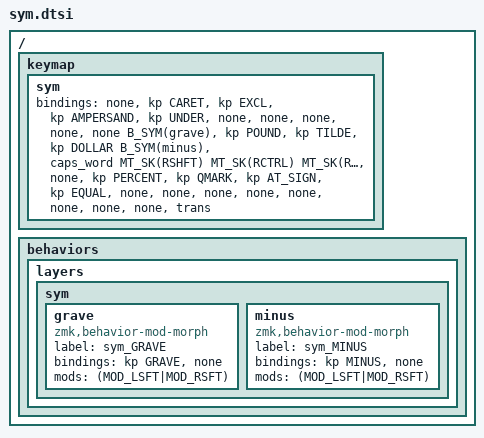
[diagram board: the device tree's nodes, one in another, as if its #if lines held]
// Copyright (c) 2022 The ZMK Contributors
// SPDX-License-Identifier: MIT

#define B_SYM(key) B_LAYER(sym, key)

/ {
    keymap {
        sym {
            bindings = <
        // ╭──────────────┬──────────────┬──────────────┬──────────────┬──────────────╮   ╭──────────────┬──────────────┬──────────────┬──────────────┬──────────────╮
        // │              |  ^           |  !           |  &           |  _           │   │              │              │              │              │              │
             &none          &kp CARET      &kp EXCL       &kp AMPERSAND  &kp UNDER          &none          &none          &none          &none          &none
        // ├──────────────┼──────────────┼──────────────┼──────────────┼──────────────┤   ├──────────────┼──────────────┼──────────────┼──────────────┼──────────────┤
        // │  `           |  #           |  ~           |  $           |  -           │   │              │  SHIFT       │  CONTROL     |  ALT         |  GUI         │
             B_SYM(grave)   &kp POUND      &kp TILDE      &kp DOLLAR     B_SYM(minus)       &caps_word     MT_SK(RSHFT)   MT_SK(RCTRL)   MT_SK(RALT)    MT_SK(RGUI)
        // ├──────────────┼──────────────┼──────────────┼──────────────┼──────────────┤   ├──────────────┼──────────────┼──────────────┼──────────────┼──────────────┤
        // │              |  %           |  ?           |  @           |  =           │   │              │              │              │              │              │
             &none          &kp PERCENT    &kp QMARK      &kp AT_SIGN    &kp EQUAL          &none          &none          &none          &none          &none
        // ╰──────────────┴──────────────┴──────────────┼──────────────┼──────────────┤   ├──────────────┼──────────────┼──────────────┴──────────────┴──────────────╯
#ifdef KEY_34
        //                                              ╭──────────────┬──────────────╮   ╭──────────────┬──────────────╮
        //                                              |              |              |   |              |              |
                                                          &none          &none              &none          &trans
        //                                              ╰──────────────┴──────────────╯   ╰──────────────┴──────────────╯
#else
        //                               ╭──────────────┬──────────────┬──────────────╮   ╭──────────────┬──────────────┬──────────────╮
        //                               |              |              |              |   |              |              |              |
                                           &none          &none          &none              &none          &trans         &none
        //                               ╰──────────────┴──────────────┴──────────────╯   ╰──────────────┴──────────────┴──────────────╯
#endif
            >;
        };
    };

    behaviors {
        layers {
            sym {
                grave {
                    compatible = "zmk,behavior-mod-morph";
                    label = "sym_GRAVE";
                    #binding-cells = <0>;
                    bindings = <&kp GRAVE>, <&none>;
                    mods = <(MOD_LSFT|MOD_RSFT)>;
                };

                minus {
                    compatible = "zmk,behavior-mod-morph";
                    label = "sym_MINUS";
                    #binding-cells = <0>;
                    bindings = <&kp MINUS>, <&none>;
                    mods = <(MOD_LSFT|MOD_RSFT)>;
                };
            };
        };
    };
};
